# iND83213A register map
Vendor: Indiemicro; Series: Rugby; File version: 1.0
CPU: CM0 r0p1, selectable endian, no MPU, no FPU, 4 interrupt priority bits
Registers are 32-bit, read-write, no defined reset value unless marked. A register's access mark holds for its fields unless they carry their own. Offsets are from the block's base; [hi:lo] are bit positions; <NAME> marks a mode.

## LINS — LIN slave interface registers
Base 0x50010300; register names take the prefix LINS_
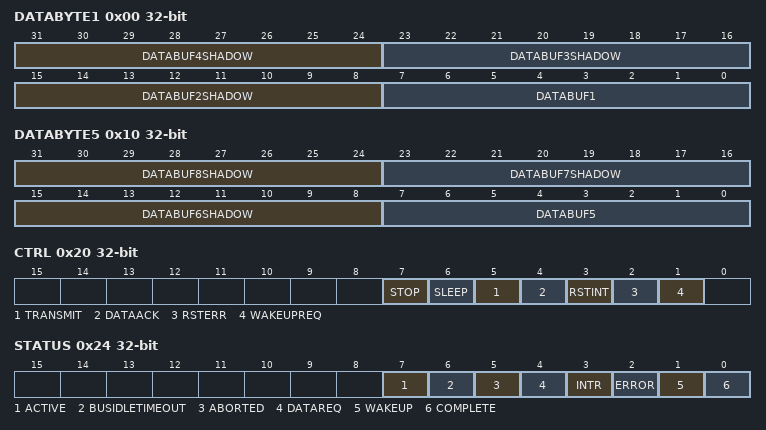
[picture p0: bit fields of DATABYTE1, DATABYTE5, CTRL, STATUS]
0x00 DATABYTE1
  [31:24] DATABUF4SHADOW — Data Buffer 2 Shadow. Shadow register of 4th byte of the 8-byte Data Buffer. Only writable when the transaction is idle.
  [23:16] DATABUF3SHADOW — Data Buffer 2 Shadow. Shadow register of 3rd byte of the 8-byte Data Buffer. Only writable when the transaction is idle.
  [15:8] DATABUF2SHADOW — Data Buffer 2 Shadow. Shadow register of 2nd byte of the 8-byte Data Buffer. Only writable when the transaction is idle.
  [7:0] DATABUF1 — Data Buffer 1. 1st byte of the 8-byte Data Buffer. Only writable when the transaction is idle.
0x04 DATABYTE2
  [7:0] DATABUF2 — Data Buffer 2. 2nd byte of the 8-byte Data Buffer. Only writable when the transaction is idle.
0x08 DATABYTE3
  [7:0] DATABUF3 — Data Buffer 3. 3rd byte of the 8-byte Data Buffer. Only writable when the transaction is idle.
0x0C DATABYTE4
  [7:0] DATABUF4 — Data Buffer 4. 4th byte of the 8-byte Data Buffer. Only writable when the transaction is idle.
0x10 DATABYTE5
  [31:24] DATABUF8SHADOW — Data Buffer 8 Shadow. Shadow register of 8th byte of the 8-byte Data Buffer. Only writable when the transaction is idle.
  [23:16] DATABUF7SHADOW — Data Buffer 7 Shadow. Shadow register of 7th byte of the 8-byte Data Buffer. Only writable when the transaction is idle.
  [15:8] DATABUF6SHADOW — Data Buffer 6 Shadow. Shadow register of 6th byte of the 8-byte Data Buffer. Only writable when the transaction is idle.
  [7:0] DATABUF5 — Data Buffer 5. 5th byte of the 8-byte Data Buffer. Only writable when the transaction is idle.
0x14 DATABYTE6
  [7:0] DATABUF6 — Data Buffer 6. 6th byte of the 8-byte Data Buffer. Only writable when the transaction is idle.
0x18 DATABYTE7
  [7:0] DATABUF7 — Data Buffer 7. 7th byte of the 8-byte Data Buffer. Only writable when the transaction is idle.
0x1C DATABYTE8
  [7:0] DATABUF8 — Data Buffer 8. 8th byte of the 8-byte Data Buffer. Only writable when the transaction is idle.
0x20 CTRL — Control Register
  [7] STOP wo — Stop Register. The host controller of the LIN slave has set this register if it handles a data request interrupt and can not make use of the frame content with the received identifier(e.g. extended identifiers). For that case the LIN slave stops the processing of the LIN communication until the next SYNC BREAK is detected. A read access to this bit delivers always the value 0 Autoclear: includes a synchronous reset signal which clears the register on the cycle following write.
  [6] SLEEP — Sleep Request. The bit is used by the LIN core to determine whether the LIN bus is in Sleep Mode or not. The host controller has to set the bit after sending or receiving a Sleep Mode frame. If DIS_AUTOSLEEP = 0, the bit will be set automatically by the LIN core if a bus idle timeout is detected. The host controller has to clear the bit after a wakeup signal is detected.
  [5] TRANSMIT — Transmit Operation. The bit determines whether the current frame is a transmit frame or a receive frame for the LIN node. It has to be set by the host controller. 0x0: receive operation 0x1: transmit operation
  [4] DATAACK — Data Acknowledgement. The bit has to be set by the host controller of a LIN slave after handling a data request interrupt (compare STATUS.DATA_REQ register). The bit will be reset by the LIN core.
  [3] RSTINT wo — Reset interrupt. The host controller has to set this bit to reset the STATUS.INTR register and the interrupt request output of the LIN core. A read access to this bit delivers always the value 0.
  [2] RSTERR wo — Reset Error. The host controller has to set this bit to reset the error bits in status register and error register. A read access to this bit delivers always the value 0.
  [1] WAKEUPREQ — WakeUp Request. The bit has to be set by the host controller to terminate the Sleep Mode of the LIN bus by sending a Wakeup signal. The bit will be reset by the LIN core.
0x24 STATUS
  [7] ACTIVE ro — Lin Bus Active. The bit indicates whether the LIN bus is active or not. Note: For the LIN slave, this bit is set after the detection of a correct SYNC BREAK / SYNC FIELD sequence and it is reset at the end of the transmission or if the processing of the current frame is stopped by the host controller 0x0: no Lin bus activity 0x1: transmission on the LIN bus is active
  [6] BUSIDLETIMEOUT ro — BUS Idle Timeout. This bit is set by the LIN core if LIN is in hardware mode and no bus activity is detected for 4s~10s. In addition, an interrupt request to the host controller is generated in that case. After that, It is assumed that the LIN bus is in sleep mode and CTRL.SLEEP register will be set by the LIN core. The bit has to be reset by the host controller by setting the bit CTRL.RST_INT register.
  [5] ABORTED ro — Aborted. The bit is set if the processing of the current frame has been stopped by setting CTRL.STOP register. The bit is cleared by the LIN core after receiving a correct SYNC BREAK / SYNC FIELD sequence
  [4] DATAREQ ro — Data Request. The LIN core slave sets the bit after receiving the Identifier and requests an interrupt to the host controller. The host controller has to decode the Identifier to decide whether the current frame is a transmit or a receive operation. It has to adjust CTRL.TRANSMIT register and to load the data length. For transmit operations it has to load the data buffer too. After that the host controller has to set CTRL.DATA_ACK register
  [3] INTR ro — Interupt Request. The LIN core sets the bit when it requests an interrupt to the host controller. It has the same value as the interrupt output INTR. The bit has to be reset by the host controller by setting the bit CTRL.RST_INT register
  [2] ERROR ro — Lin Error. The LIN core sets the bit if an error has been detected (compare error register). The bit has to be reset by the host controller by setting the bit CTRL.RST_ERR register
  [1] WAKEUP ro — WakeUp. The bit is set when the LIN core is transmitting a Wakeup signal.
  [0] COMPLETE ro — Complete. The LIN core will set the bit after a transmission has been successfully finished and it will reset it at the start of a transmission
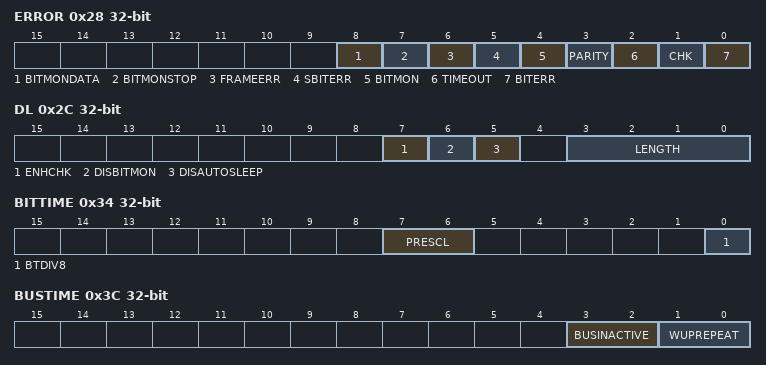
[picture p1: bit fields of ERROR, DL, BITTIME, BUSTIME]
0x28 ERROR
  [8] BITMONDATA ro — Bit Monitor Error occurred in Start or Data Bits. The Bit value monitored on the bus is different from the sent bit value and the error occurrs on the start or data bits.
  [7] BITMONSTOP ro — Bit Monitor Error occurred in Stop Bit. The Bit value monitored on the bus is different from the sent bit value and the error occurrs on the stop bit. In SAE2602, the error belongs to framing error.
  [6] FRAMEERR ro — Byte Field Framing Error. This bit is set by the LIN core slave if a transmission is aborted after the beginning of the data field due to a timeout or an incomplete frame
  [5] SBITERR ro — Start Bit Error in Byte field. Start Bit Error in Byte field, i.e., invalid start bit.
  [4] BITMON ro — Bit Monitor Error. The Bit value monitored on the bus is different from the sent bit value, bit monitor error will trigger an interrupt
  [3] PARITY ro — Parity Error. Identifier parity error
  [2] TIMEOUT ro — Timeout Error. There are several reason that can cause a timeout error: The master detects a timeout error if it is expecting data from the bus but no slave does respond. If the slave responds to late and the frame is not finished within the maximum frame length TFRAME_MAX a timeout error will be detected too. The slave detects a timeout error if it is requesting a data acknowledge to the host controller (for selecting receive or transmit, data length and loading data), and the host controller does not set CTRL.DATA_ACK or CTRL.STOP register until the end of the reception of the first byte after the identifier. The slave detects a timeout error if it has transmitted a wakeup signal and it detects no sync field (from the master) within 150 ms. Note: The slave does not perform an exact check of the frame length TFRAME_MAX but a timeout is detected after 200 bit times, if the slave is in receive mode and there are missing data fields or a missing ID field from the master.
  [1] CHK ro — Checksum Error. Checksum Error
  [0] BITERR ro — Bit Error in Byte field. Bit Error in Byte field, i.e., invalid stop bit.
0x2C DL — DATA Length Register
  [7] ENHCHK — Enhancement Check. The host controller has to set the checksum type used in the current frame by adjusting this register. 0x0: for classic checksum 0x1: for enhanced checksum
  [6] DISBITMON — Disable Bit Monitor. Set to disable the bit monitor during transmission. The bit must be set in case that RXD/TXD are separated.
  [5] DISAUTOSLEEP — Disable Auto Sleep. Set to Disable auto sleep.
  [3:0] LENGTH — Data Length. The host controller has to define the length of the data field of the current LIN frame by adjusting the data length register. If the data length is loaded with the value 1111b the length of the data field is decoded from Bit 5 and 4 of the identifier register id according to the Table below (e.g. compatibility to LIN specification 1.1). Otherwise the amount of data bytes can be written directly to the data length register (supported values are 0..8). <table> <thead><tr> <th> ID (Bit 5) </th> <th> ID (Bit 4) </th> <th> Number of Bytes in the data field </th> </tr></thead><tbody><tr> <td> 0 </td> <td> 0 </td> <td> 2 </td> </tr> <tr> <td> 0 </td> <td> 1 </td> <td> 2 </td> </tr> <tr> <td> 1 </td> <td> 0 </td> <td> 4 </td> </tr> <tr> <td> 1 </td> <td> 1 </td> <td> 8 </td> </tr></tbody></table>
0x30 BTDIV07 — Bit time Divider Register
  [7:0] BTDIV07 — Bt Div LSBs. Bit time divider [7:0]
0x34 BITTIME — Control Settings
  [7:6] PRESCL — Prescaler Register. Prescaler Setting
  [0] BTDIV8 — Bt Div Most Significant bit. Bit time divider [8]
0x38 ID
  [5:0] ID — ID. ID register
0x3C BUSTIME — Lin Bus Timing Register
  [3:2] BUSINACTIVE — Bus Inactivity Time.
  [1:0] WUPREPEAT — wakeup repeat time.
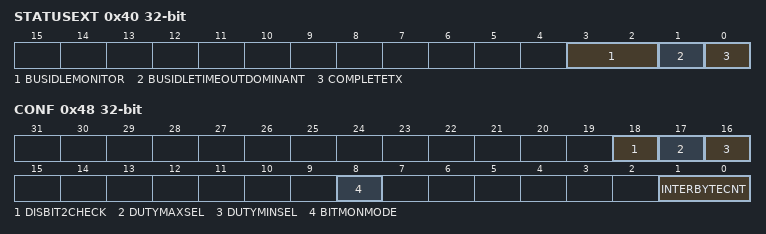
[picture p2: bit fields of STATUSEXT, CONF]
0x40 STATUSEXT — Extended Status
  [3:2] BUSIDLEMONITOR ro — Bus Idle Monitor Status. If LIN is in hardware mode, BIT[0] is set by the lin core if the bus has no activity for 4s~10s and BIT[1] is set by the lin core if LIN is stuck at dominant inactivity state for 4s~10s. Any bus transition will clear these two bits. LIN Slave's pullup will be disabled & LIN Master's pullup will be reduced to 30K when BIT[1] is set.
  [1] BUSIDLETIMEOUTDOMINANT ro — Dominant Bus Idle Timeout. The bit is set by the lin core if LIN is in hardware mode & the bus is stuck at dominant inactivity state for 4s~10s. The bit has to be reset by the host controller by setting the bit CTRL.RST_INT register.
  [0] COMPLETETX ro — Complete TX. The LIN core will set the bit after a TX transmission has been successfully finished and it will reset it at the start of a transmission.
0x48 CONF — Extended Configuration Register for compatibility issue
  [18] DISBIT2CHECK — Disable Two Bits Width Check. Set to disable two bits width check for sync field. 0x0: Default.If the width mismatch is >25% between any two close bits and the 1st two bits, the byte will not be taken as a sync field. 0x1: Disabled. Recommended for the fast mode case that its baud rate is >=250KHz.
  [17] DUTYMAXSEL — Maximum Duty Select. Select the maximum duty constraint for sync field check. 0x0: Default. Check will fail if Duty > 68.75%. 0x1: Check will fail if Duty > 62.5%.
  [16] DUTYMINSEL — Minimum Duty Select. Select the minimum duty constraint for sync field check. 0x0: Default. Check will fail if Duty < 31.25%. 0x1: Check will fail if Duty < 37.5%.
  [8] BITMONMODE — BIT Monitor Mode. Control the exit timing when bit monitor error occured. Only writable when the transaction is idle. 0x0: Default. The transmission finished immediately if bit_mon is detected. 0x1: Even bit_mon is detected, the transmission will not be finished until the byte transfer is completed.
  [1:0] INTERBYTECNT — Inter-Byte Space Bit Count. Bit count of inter-byte space. >= 1bit inter-byte space is required by some legacy LIN devices. Only writable when the transaction is idle.
0x4C BAUDCTRL — BaudRate Control
  [14:0] BTDIVSYNC — Bit BaudRate Divider. Bit BaudRate = Fsys/(2**PRESCL)/BT_DIV_SYNC. The register is automatically updated once a legal sync field is received.
